# ASR6601 register map
Vendor: ASR Microelectronics; Series: ASR6601; File version: 1.1
CPU: CM4 r0p1, little endian, no MPU, FPU, VTOR, 3 interrupt priority bits
Registers are 32-bit, read-write, no defined reset value unless marked. A register's access mark holds for its fields unless they carry their own. Offsets are from the block's base; [hi:lo] are bit positions; lines under a group give offsets from that group; {n}, {i} and the like mark numbered series.

## SEC — Security controller
Base 0x4000F000
0x00 INT — interrupt enable register
0x04 RST — reset enable register
0x08 SR — status
  [12] FLASH_ACCESS_ERROR
{0xC+4i} FILTER{i} (i=0..3)

## ADC — 12-bit analog-to-digital converter
Base 0x40017000
0x00 CR — control register
0x04 CFGR — configuration register
0x08 SEQR0 — sequence0 register
0x0C SEQR1 — sequence1 register
0x10 DIFFSEL — difference register
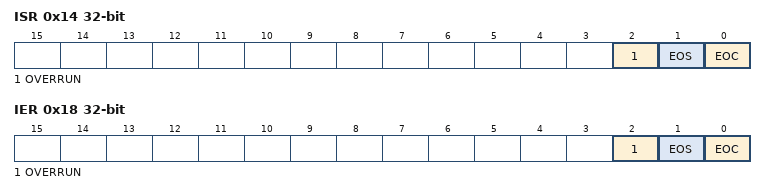
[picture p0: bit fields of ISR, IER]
0x14 ISR — interrupt status register
  [2] OVERRUN, [1] EOS, [0] EOC
0x18 IER — interrupt enable register
  [2] OVERRUN, [1] EOS, [0] EOC
0x1C DR ro — data register
{0x20+4i} AWD{i}_CFGR (i=0..2) — AWD{i} register

## LCD — Segment LCD controller
Base 0x40018000
0x00 CR0 — control register 0
  [0] DONE_STATUS
0x04 CR1 — control register 1
  [1] DONE_STATUS
{0x8+4i} DR{i} (i=0..7) — data register {i}
0x28 SR ro — status register
0x2C CR2 — control register 2

## DAC — 12-bit digital-to-analog converter
Base 0x40019000
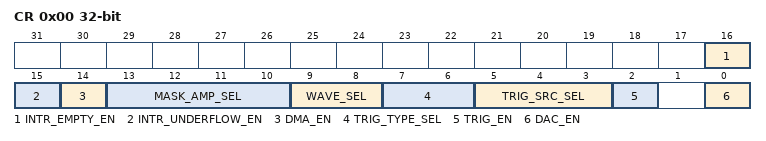
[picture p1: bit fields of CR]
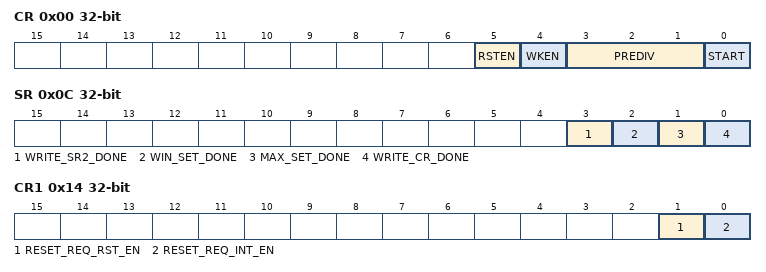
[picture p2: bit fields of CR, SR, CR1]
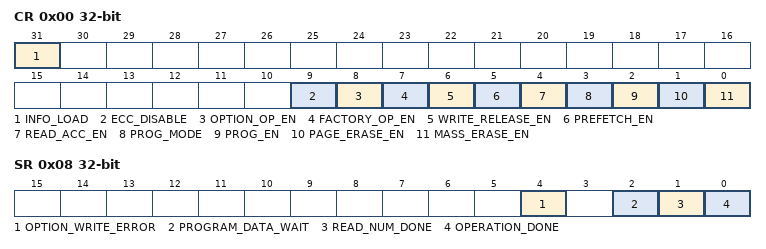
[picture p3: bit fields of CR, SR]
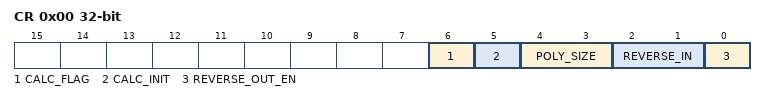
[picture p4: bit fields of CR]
0x00 CR — control register
  [16] INTR_EMPTY_EN
  [15] INTR_UNDERFLOW_EN
  [14] DMA_EN
  [13:10] MASK_AMP_SEL
    0=VALUE_1; 9=VALUE_1023; 6=VALUE_127; 3=VALUE_15; 7=VALUE_255; 1=VALUE_3; 4=VALUE_31; 8=VALUE_511; 5=VALUE_63; 2=VALUE_7
  [9:8] WAVE_SEL
    1=NOISE; 0=NONE; 2=TRIANGLE
  [7:6] TRIG_TYPE_SEL
    1=FALLING_EDGE; 0=RISING_EDGE; 2=RISING_FALLING_EDGE
  [5:3] TRIG_SRC_SEL
    3=BSTIMER0_TRGO; 2=BSTIMER1_TRGO; 5=GPIO24; 6=GPIO43; 4=GPIO6; 1=GPTIMER0_TRGO; 0=GPTIMER1_TRGO; 7=SOFTWARE
  [2] TRIG_EN
  [0] DAC_EN
0x04 SWTRIGR wo — software trigger register
0x08 DHR — data holding register
0x0C DOR ro — data output register
0x10 SR — status register

## IWDG — Independent watchdog
Base 0x4001D000
0x00 CR — control register
  [5] RSTEN
  [4] WKEN
  [3:1] PREDIV
    5=VALUE_128; 2=VALUE_16; 6=VALUE_256; 3=VALUE_32; 0=VALUE_4; 4=VALUE_64; 1=VALUE_8
  [0] START
0x04 MAX — max value register
0x08 WIN — window value register
0x0C SR ro — status register
  [3] WRITE_SR2_DONE, [2] WIN_SET_DONE, [1] MAX_SET_DONE, [0] WRITE_CR_DONE
0x10 SR1 ro — status register 1
  [12] RESET_REQ_SYNC
0x14 CR1 — control register 1
  [1] RESET_REQ_RST_EN, [0] RESET_REQ_INT_EN
0x18 SR2 — status register 2
  [0] RESET_REQ_SR

## WDG — Watchdog timer
Base 0x4001E000
0x00 LOAD
0x04 VALUE ro
0x08 CONTROL
0x0C INTCLR wo — clear interrupt register
0x10 RIS ro — raw interrupt status register
0x14 MIS ro — interrupt status register
0xC00 LOCK
0xF00 ITCR — integration test control register
0xF04 ITOP wo — integration test output set register
{0xFC0+4i} PERIPHID{i} ro (i=4..7) — peripheral id register {i}
{0xFE0+4i} PERIPHID{i} ro (i=0..3) — peripheral id register {i}
{0xFF0+4i} PCELLID{i} ro (i=0..3) — component id register {i}

## GPIOA
Base 0x4001F000
Same registers: GPIOB 0x4001F400, GPIOC 0x4001F800, GPIOD 0x4001FC00
0x00 OER — output enable register
0x04 OTYPER — output type register
0x08 IER — input enable register
0x0C PER — pull enable register
0x10 PSR — pull select register
0x14 IDR ro — input data register
0x18 ODR — output data register
0x1C BRR wo — bit reset register
0x20 BSR wo — bit set register
0x24 DSR — dirve set register
0x28 ICR — interrupt control register
0x2C IFR — interrupt flag register
0x30 WUCR — wakeup control register
0x34 WULVL — wakeup level register
0x38 AFRL — alternate function low register
0x3C AFRH — alternate function high register
0x40 STOP3_WUCR — stop3 wakeup control register

## EFC — Embedded flash controller
Base 0x40020000
0x00 CR — control register
  [31] INFO_LOAD
  [9] ECC_DISABLE
  [8] OPTION_OP_EN
  [7] FACTORY_OP_EN
  [6] WRITE_RELEASE_EN
  [5] PREFETCH_EN
  [4] READ_ACC_EN
  [3] PROG_MODE
    0=DWORD; 1=WLINE
  [2] PROG_EN
  [1] PAGE_ERASE_EN
  [0] MASS_ERASE_EN
0x04 INT_EN — interrupt enable register
0x08 SR — status register
  [4] OPTION_WRITE_ERROR, [2] PROGRAM_DATA_WAIT, [1] READ_NUM_DONE, [0] OPERATION_DONE write-1-clears
0x0C PROGRAM_DATA0
0x10 PROGRAM_DATA1
0x14 TIMING_CFG — timing config register
  [19:16] READ_NUM
0x18 PROTECT_SEQ wo — protect sequence register
0x20 CHIP_PATTERN ro
0x24 IP_TRIM_L ro — analog ip trimming low register
0x28 IP_TRIM_H ro — analog ip trimming high register
0x2C SN_L ro — serial number low register
0x30 SN_H ro — serial number high register
0x34 TEST_INFO_L ro — test info low register
0x38 TEST_INFO_H ro — test info high register
0x3C OPTION_CSR_BYTES ro — option control and status register
0x40 OPTION_EO_BYTES ro — option exe-only bytes register
0x44 OPTION_WP_BYTES ro — option write-protect bytes register
0x48 OPTION_SEC_BYTES0 ro — option secure byte 0 register
0x4C OPTION_SEC_BYTES1 ro — option secure byte 1 register

## CRC — CRC calculation unit
Base 0x40022000
0x00 CR — control register
  [6] CALC_FLAG
  [5] CALC_INIT
  [4:3] POLY_SIZE
    1=VALUE_16; 0=VALUE_32; 3=VALUE_7; 2=VALUE_8
  [2:1] REVERSE_IN
    1=BYTE; 2=HWORD; 0=NONE; 3=WORD
  [0] REVERSE_OUT_EN
0x04 DR — data register
0x08 INIT — init value register
0x0C POLY — polynomial register

## DMA0 — DMA Controller 0
Base 0x40023000
Same registers: DMA1 0x40024000
{0x0+0x58*i} CH{i} (i=0..3) group — DMA Channel
  0x00 SAR_L
  0x04 SAR_H
  0x08 DAR_L
  0x0C DAR_H
  0x10 LLP_L
  0x14 LLP_H
  0x18 CTL_L
  0x1C CTL_H
  0x20 SSTAT_L
  0x24 SSTAT_H
  0x28 DSTAT_L
  0x2C DSTAT_H
  0x30 SSTATAR_L
  0x34 SSTATAR_H
  0x38 DSTATAR_L
  0x3C DSTATAR_H
  0x40 CFG_L
  0x44 CFG_H
  0x48 SGR_L
  0x4C SGR_H
  0x50 DSR_L
  0x54 DSR_H
0x2C0 RAW_TFR_L
0x2C4 RAW_TFR_H
0x2C8 RAW_BLOCK_L
0x2CC RAW_BLOCK_H
0x2E8 STATUS_TFR_L
0x2EC STATUS_TFR_H
0x2F0 STATUS_BLOCK_L
0x2F4 STATUS_BLOCK_H
0x310 MASK_TFR_L
0x314 MASK_TFR_H
0x318 MASK_BLOCK_L
0x31C MASK_BLOCK_H
0x338 CLEAR_TFR_L
0x33C CLEAR_TFR_H
0x340 CLEAR_BLOCK_L
0x344 CLEAR_BLOCK_H
0x348 CLEAR_SRC_TRAN_L
0x34C CLEAR_SRC_TRAN_H
0x350 CLEAR_DST_TRAN_L
0x354 CLEAR_DST_TRAN_H
0x358 CLEAR_ERR_L
0x35C CLEAR_ERR_H
0x360 STATUS_INT
0x368 REQ_SRC
0x370 REQ_DST
0x378 SGL_REQ_SRC
0x380 SGL_REQ_DST
0x398 DMACFGREG_L
0x39C DMACFGREG_H
0x3A0 CHENREG_L
0x3A4 CHENREG_H
0x3E0 DMA_COMP_PARAMS_3_L
0x3E4 DMA_COMP_PARAMS_3_H
0x3E8 DMA_COMP_PARAMS_2_L
0x3EC DMA_COMP_PARAMS_2_H
0x3F0 DMA_COMP_PARAMS_1_L
0x3F4 DMA_COMP_PARAMS_1_H

## SAE — Security algorithm engine
Base 0x40032000
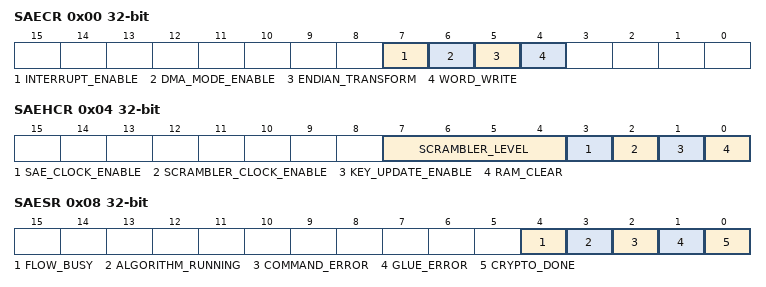
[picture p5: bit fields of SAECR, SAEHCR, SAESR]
0x00 SAECR — Common control register
  [7] INTERRUPT_ENABLE, [6] DMA_MODE_ENABLE, [5] ENDIAN_TRANSFORM, [4] WORD_WRITE
0x04 SAEHCR — Security control register
  [7:4] SCRAMBLER_LEVEL, [3] SAE_CLOCK_ENABLE, [2] SCRAMBLER_CLOCK_ENABLE, [1] KEY_UPDATE_ENABLE, [0] RAM_CLEAR
0x08 SAESR — Status register
  [4] FLOW_BUSY, [3] ALGORITHM_RUNNING, [2] COMMAND_ERROR, [1] GLUE_ERROR, [0] CRYPTO_DONE
{0xC+4i} SAEGPR{i} (i=0..5) — General-purpose register {i}
0x24 SAEMASKCR — Mask control register
  [0] MASK_ENABLE
{0x28+4i} SAEMASKDAT{i} (i=0..2) — Mask data register {i}
0x34 SAEBUFCR — Buffer control register

## RNG — Hardware random-number generator
Base 0x40033000
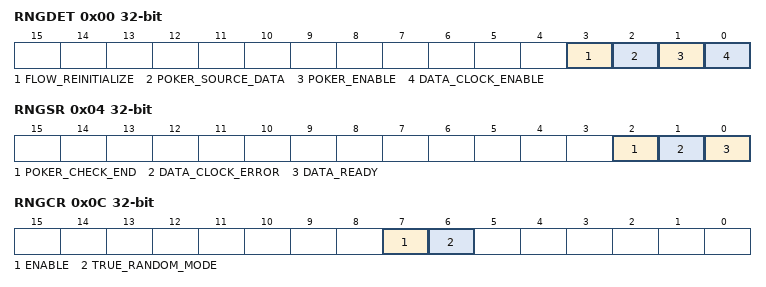
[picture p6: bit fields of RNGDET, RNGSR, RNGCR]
0x00 RNGDET — Detection control register
  [3] FLOW_REINITIALIZE, [2] POKER_SOURCE_DATA, [1] POKER_ENABLE, [0] DATA_CLOCK_ENABLE
0x04 RNGSR — Status register
  [2] POKER_CHECK_END, [1] DATA_CLOCK_ERROR, [0] DATA_READY
0x08 RNGCLK — Clock control register
  [7] CLOCK_ENABLE
0x0C RNGCR — Control register
  [7] ENABLE, [6] TRUE_RANDOM_MODE
0x10 RNGRESEED — Reseed register
0x14 RNGDATA — Random data register
0x18 RNGPKNUM — Poker test sample count
{0x1C+4i} RNGPKRES{i} (i=0..2) — Poker test result {i}
